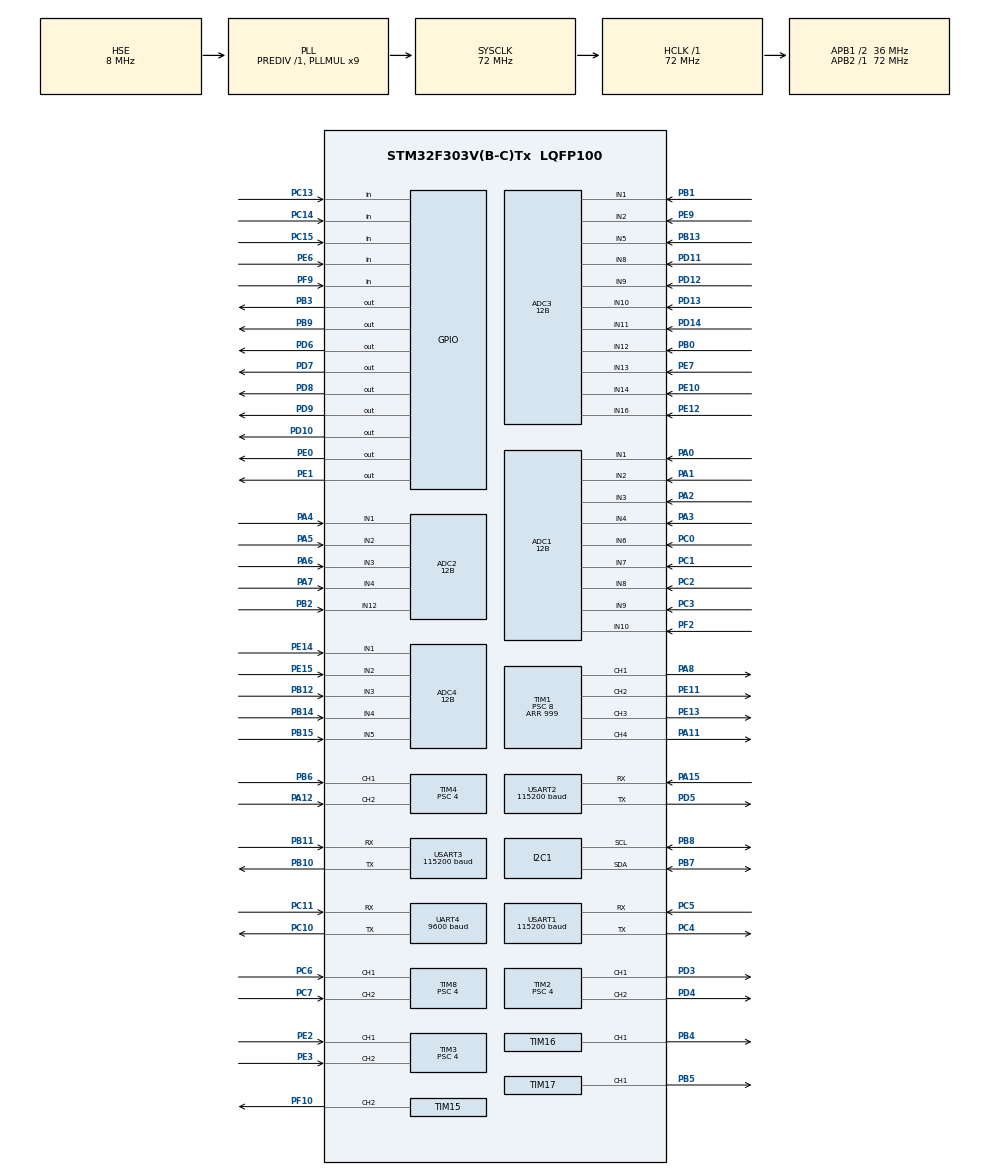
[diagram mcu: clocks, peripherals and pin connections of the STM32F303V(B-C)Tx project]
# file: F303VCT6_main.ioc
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ADC1.Channel-0\#ChannelRegularConversion=ADC_CHANNEL_1
ADC1.Channel-1\#ChannelRegularConversion=ADC_CHANNEL_2
ADC1.Channel-2\#ChannelRegularConversion=ADC_CHANNEL_3
ADC1.Channel-3\#ChannelRegularConversion=ADC_CHANNEL_4
ADC1.Channel-4\#ChannelRegularConversion=ADC_CHANNEL_6
ADC1.Channel-5\#ChannelRegularConversion=ADC_CHANNEL_7
ADC1.Channel-6\#ChannelRegularConversion=ADC_CHANNEL_8
ADC1.Channel-7\#ChannelRegularConversion=ADC_CHANNEL_9
ADC1.Channel-9\#ChannelRegularConversion=ADC_CHANNEL_10
ADC1.ClockPrescaler=ADC_CLOCK_SYNC_PCLK_DIV4
ADC1.ContinuousConvMode=ENABLE
ADC1.DMAContinuousRequests=ENABLE
ADC1.DataAlign=ADC_DATAALIGN_RIGHT
ADC1.DiscontinuousConvMode=DISABLE
ADC1.EOCSelection=ADC_EOC_SINGLE_CONV
ADC1.EnableAnalogWatchDog1=false
ADC1.EnableAnalogWatchDog2=false
ADC1.EnableAnalogWatchDog3=false
ADC1.EnableInjectedConversion=DISABLE
ADC1.EnableRegularConversion=ENABLE
ADC1.ExternalTrigConv=ADC_SOFTWARE_START
ADC1.ExternalTrigConvEdge=ADC_EXTERNALTRIGCONVEDGE_NONE
ADC1.LowPowerAutoWait=DISABLE
ADC1.NbrOfConversion=9
ADC1.NbrOfConversionFlag=1
ADC1.Offset-0\#ChannelRegularConversion=0
ADC1.Offset-1\#ChannelRegularConversion=0
ADC1.Offset-2\#ChannelRegularConversion=0
ADC1.Offset-3\#ChannelRegularConversion=0
ADC1.Offset-4\#ChannelRegularConversion=0
ADC1.Offset-5\#ChannelRegularConversion=0
ADC1.Offset-6\#ChannelRegularConversion=0
ADC1.Offset-7\#ChannelRegularConversion=0
ADC1.Offset-9\#ChannelRegularConversion=0
ADC1.OffsetNumber-0\#ChannelRegularConversion=ADC_OFFSET_NONE
ADC1.OffsetNumber-1\#ChannelRegularConversion=ADC_OFFSET_NONE
ADC1.OffsetNumber-2\#ChannelRegularConversion=ADC_OFFSET_NONE
ADC1.OffsetNumber-3\#ChannelRegularConversion=ADC_OFFSET_NONE
ADC1.OffsetNumber-4\#ChannelRegularConversion=ADC_OFFSET_NONE
ADC1.OffsetNumber-5\#ChannelRegularConversion=ADC_OFFSET_NONE
ADC1.OffsetNumber-6\#ChannelRegularConversion=ADC_OFFSET_NONE
ADC1.OffsetNumber-7\#ChannelRegularConversion=ADC_OFFSET_NONE
ADC1.OffsetNumber-9\#ChannelRegularConversion=ADC_OFFSET_NONE
ADC1.Overrun=ADC_OVR_DATA_OVERWRITTEN
ADC1.Rank-0\#ChannelRegularConversion=1
ADC1.Rank-1\#ChannelRegularConversion=2
ADC1.Rank-2\#ChannelRegularConversion=3
ADC1.Rank-3\#ChannelRegularConversion=4
ADC1.Rank-4\#ChannelRegularConversion=5
ADC1.Rank-5\#ChannelRegularConversion=6
ADC1.Rank-6\#ChannelRegularConversion=7
ADC1.Rank-7\#ChannelRegularConversion=8
ADC1.Rank-9\#ChannelRegularConversion=9
ADC1.Resolution=ADC_RESOLUTION_12B
ADC1.SamplingTime-0\#ChannelRegularConversion=ADC_SAMPLETIME_181CYCLES_5
ADC1.SamplingTime-1\#ChannelRegularConversion=ADC_SAMPLETIME_181CYCLES_5
ADC1.SamplingTime-2\#ChannelRegularConversion=ADC_SAMPLETIME_181CYCLES_5
ADC1.SamplingTime-3\#ChannelRegularConversion=ADC_SAMPLETIME_181CYCLES_5
ADC1.SamplingTime-4\#ChannelRegularConversion=ADC_SAMPLETIME_181CYCLES_5
ADC1.SamplingTime-5\#ChannelRegularConversion=ADC_SAMPLETIME_181CYCLES_5
ADC1.SamplingTime-6\#ChannelRegularConversion=ADC_SAMPLETIME_181CYCLES_5
ADC1.SamplingTime-7\#ChannelRegularConversion=ADC_SAMPLETIME_181CYCLES_5
ADC1.SamplingTime-9\#ChannelRegularConversion=ADC_SAMPLETIME_181CYCLES_5
ADC1.ScanConvMode=ADC_SCAN_ENABLE
ADC1.master=1
ADC2.Channel-0\#ChannelRegularConversion=ADC_CHANNEL_1
ADC2.Channel-1\#ChannelRegularConversion=ADC_CHANNEL_2
ADC2.Channel-2\#ChannelRegularConversion=ADC_CHANNEL_3
ADC2.Channel-3\#ChannelRegularConversion=ADC_CHANNEL_4
ADC2.Channel-4\#ChannelRegularConversion=ADC_CHANNEL_12
ADC2.ClockPrescaler=ADC_CLOCK_SYNC_PCLK_DIV4
ADC2.ContinuousConvMode=ENABLE
ADC2.DMAContinuousRequests=ENABLE
ADC2.DataAlign=ADC_DATAALIGN_RIGHT
ADC2.DiscontinuousConvMode=DISABLE
ADC2.EOCSelection=ADC_EOC_SINGLE_CONV
ADC2.EnableAnalogWatchDog1=false
ADC2.EnableAnalogWatchDog2=false
ADC2.EnableAnalogWatchDog3=false
ADC2.EnableInjectedConversion=DISABLE
ADC2.EnableRegularConversion=ENABLE
ADC2.ExternalTrigConv=ADC_SOFTWARE_START
ADC2.ExternalTrigConvEdge=ADC_EXTERNALTRIGCONVEDGE_NONE
ADC2.LowPowerAutoWait=DISABLE
ADC2.NbrOfConversion=5
ADC2.NbrOfConversionFlag=1
ADC2.Offset-0\#ChannelRegularConversion=0
ADC2.Offset-1\#ChannelRegularConversion=0
ADC2.Offset-2\#ChannelRegularConversion=0
ADC2.Offset-3\#ChannelRegularConversion=0
ADC2.Offset-4\#ChannelRegularConversion=0
ADC2.OffsetNumber-0\#ChannelRegularConversion=ADC_OFFSET_NONE
ADC2.OffsetNumber-1\#ChannelRegularConversion=ADC_OFFSET_NONE
ADC2.OffsetNumber-2\#ChannelRegularConversion=ADC_OFFSET_NONE
ADC2.OffsetNumber-3\#ChannelRegularConversion=ADC_OFFSET_NONE
ADC2.OffsetNumber-4\#ChannelRegularConversion=ADC_OFFSET_NONE
ADC2.Overrun=ADC_OVR_DATA_OVERWRITTEN
ADC2.Rank-0\#ChannelRegularConversion=1
ADC2.Rank-1\#ChannelRegularConversion=2
ADC2.Rank-2\#ChannelRegularConversion=3
ADC2.Rank-3\#ChannelRegularConversion=4
ADC2.Rank-4\#ChannelRegularConversion=5
ADC2.Resolution=ADC_RESOLUTION_12B
ADC2.SamplingTime-0\#ChannelRegularConversion=ADC_SAMPLETIME_181CYCLES_5
ADC2.SamplingTime-1\#ChannelRegularConversion=ADC_SAMPLETIME_181CYCLES_5
ADC2.SamplingTime-2\#ChannelRegularConversion=ADC_SAMPLETIME_181CYCLES_5
ADC2.SamplingTime-3\#ChannelRegularConversion=ADC_SAMPLETIME_181CYCLES_5
ADC2.SamplingTime-4\#ChannelRegularConversion=ADC_SAMPLETIME_181CYCLES_5
ADC2.ScanConvMode=ADC_SCAN_ENABLE
ADC3.Channel-0\#ChannelRegularConversion=ADC_CHANNEL_1
ADC3.Channel-1\#ChannelRegularConversion=ADC_CHANNEL_2
ADC3.Channel-10\#ChannelRegularConversion=ADC_CHANNEL_16
ADC3.Channel-2\#ChannelRegularConversion=ADC_CHANNEL_5
ADC3.Channel-3\#ChannelRegularConversion=ADC_CHANNEL_8
ADC3.Channel-4\#ChannelRegularConversion=ADC_CHANNEL_9
ADC3.Channel-5\#ChannelRegularConversion=ADC_CHANNEL_10
ADC3.Channel-6\#ChannelRegularConversion=ADC_CHANNEL_11
ADC3.Channel-7\#ChannelRegularConversion=ADC_CHANNEL_12
ADC3.Channel-8\#ChannelRegularConversion=ADC_CHANNEL_13
ADC3.Channel-9\#ChannelRegularConversion=ADC_CHANNEL_14
ADC3.ClockPrescaler=ADC_CLOCK_SYNC_PCLK_DIV4
ADC3.ContinuousConvMode=ENABLE
ADC3.DMAContinuousRequests=ENABLE
ADC3.DataAlign=ADC_DATAALIGN_RIGHT
ADC3.DiscontinuousConvMode=DISABLE
ADC3.EOCSelection=ADC_EOC_SINGLE_CONV
ADC3.EnableAnalogWatchDog1=false
ADC3.EnableAnalogWatchDog2=false
ADC3.EnableAnalogWatchDog3=false
ADC3.EnableInjectedConversion=DISABLE
ADC3.EnableRegularConversion=ENABLE
ADC3.ExternalTrigConv=ADC_SOFTWARE_START
ADC3.ExternalTrigConvEdge=ADC_EXTERNALTRIGCONVEDGE_NONE
ADC3.LowPowerAutoWait=DISABLE
ADC3.NbrOfConversion=11
ADC3.NbrOfConversionFlag=1
ADC3.Offset-0\#ChannelRegularConversion=0
ADC3.Offset-1\#ChannelRegularConversion=0
ADC3.Offset-10\#ChannelRegularConversion=0
ADC3.Offset-2\#ChannelRegularConversion=0
ADC3.Offset-3\#ChannelRegularConversion=0
ADC3.Offset-4\#ChannelRegularConversion=0
ADC3.Offset-5\#ChannelRegularConversion=0
ADC3.Offset-6\#ChannelRegularConversion=0
ADC3.Offset-7\#ChannelRegularConversion=0
ADC3.Offset-8\#ChannelRegularConversion=0
ADC3.Offset-9\#ChannelRegularConversion=0
ADC3.OffsetNumber-0\#ChannelRegularConversion=ADC_OFFSET_NONE
ADC3.OffsetNumber-1\#ChannelRegularConversion=ADC_OFFSET_NONE
ADC3.OffsetNumber-10\#ChannelRegularConversion=ADC_OFFSET_NONE
ADC3.OffsetNumber-2\#ChannelRegularConversion=ADC_OFFSET_NONE
ADC3.OffsetNumber-3\#ChannelRegularConversion=ADC_OFFSET_NONE
ADC3.OffsetNumber-4\#ChannelRegularConversion=ADC_OFFSET_NONE
ADC3.OffsetNumber-5\#ChannelRegularConversion=ADC_OFFSET_NONE
ADC3.OffsetNumber-6\#ChannelRegularConversion=ADC_OFFSET_NONE
ADC3.OffsetNumber-7\#ChannelRegularConversion=ADC_OFFSET_NONE
ADC3.OffsetNumber-8\#ChannelRegularConversion=ADC_OFFSET_NONE
ADC3.OffsetNumber-9\#ChannelRegularConversion=ADC_OFFSET_NONE
ADC3.Overrun=ADC_OVR_DATA_OVERWRITTEN
ADC3.Rank-0\#ChannelRegularConversion=1
ADC3.Rank-1\#ChannelRegularConversion=2
ADC3.Rank-10\#ChannelRegularConversion=11
ADC3.Rank-2\#ChannelRegularConversion=3
ADC3.Rank-3\#ChannelRegularConversion=4
ADC3.Rank-4\#ChannelRegularConversion=5
ADC3.Rank-5\#ChannelRegularConversion=6
ADC3.Rank-6\#ChannelRegularConversion=7
ADC3.Rank-7\#ChannelRegularConversion=8
ADC3.Rank-8\#ChannelRegularConversion=9
ADC3.Rank-9\#ChannelRegularConversion=10
ADC3.Resolution=ADC_RESOLUTION_12B
ADC3.SamplingTime-0\#ChannelRegularConversion=ADC_SAMPLETIME_181CYCLES_5
ADC3.SamplingTime-1\#ChannelRegularConversion=ADC_SAMPLETIME_181CYCLES_5
ADC3.SamplingTime-10\#ChannelRegularConversion=ADC_SAMPLETIME_181CYCLES_5
ADC3.SamplingTime-2\#ChannelRegularConversion=ADC_SAMPLETIME_181CYCLES_5
ADC3.SamplingTime-3\#ChannelRegularConversion=ADC_SAMPLETIME_181CYCLES_5
ADC3.SamplingTime-4\#ChannelRegularConversion=ADC_SAMPLETIME_181CYCLES_5
ADC3.SamplingTime-5\#ChannelRegularConversion=ADC_SAMPLETIME_181CYCLES_5
ADC3.SamplingTime-6\#ChannelRegularConversion=ADC_SAMPLETIME_181CYCLES_5
ADC3.SamplingTime-7\#ChannelRegularConversion=ADC_SAMPLETIME_181CYCLES_5
ADC3.SamplingTime-8\#ChannelRegularConversion=ADC_SAMPLETIME_181CYCLES_5
ADC3.SamplingTime-9\#ChannelRegularConversion=ADC_SAMPLETIME_181CYCLES_5
ADC3.ScanConvMode=ADC_SCAN_ENABLE
ADC3.master=1
ADC4.Channel-0\#ChannelRegularConversion=ADC_CHANNEL_1
ADC4.Channel-1\#ChannelRegularConversion=ADC_CHANNEL_2
ADC4.Channel-2\#ChannelRegularConversion=ADC_CHANNEL_3
ADC4.Channel-3\#ChannelRegularConversion=ADC_CHANNEL_4
ADC4.Channel-4\#ChannelRegularConversion=ADC_CHANNEL_5
ADC4.ClockPrescaler=ADC_CLOCK_SYNC_PCLK_DIV4
ADC4.ContinuousConvMode=ENABLE
ADC4.DMAContinuousRequests=ENABLE
ADC4.DataAlign=ADC_DATAALIGN_RIGHT
ADC4.DiscontinuousConvMode=DISABLE
ADC4.EOCSelection=ADC_EOC_SINGLE_CONV
ADC4.EnableAnalogWatchDog1=false
ADC4.EnableAnalogWatchDog2=false
ADC4.EnableAnalogWatchDog3=false
ADC4.EnableInjectedConversion=DISABLE
ADC4.EnableRegularConversion=ENABLE
ADC4.ExternalTrigConv=ADC_SOFTWARE_START
ADC4.ExternalTrigConvEdge=ADC_EXTERNALTRIGCONVEDGE_NONE
ADC4.LowPowerAutoWait=DISABLE
ADC4.NbrOfConversion=5
ADC4.NbrOfConversionFlag=1
ADC4.Offset-0\#ChannelRegularConversion=0
ADC4.Offset-1\#ChannelRegularConversion=0
ADC4.Offset-2\#ChannelRegularConversion=0
ADC4.Offset-3\#ChannelRegularConversion=0
ADC4.Offset-4\#ChannelRegularConversion=0
ADC4.OffsetNumber-0\#ChannelRegularConversion=ADC_OFFSET_NONE
ADC4.OffsetNumber-1\#ChannelRegularConversion=ADC_OFFSET_NONE
ADC4.OffsetNumber-2\#ChannelRegularConversion=ADC_OFFSET_NONE
ADC4.OffsetNumber-3\#ChannelRegularConversion=ADC_OFFSET_NONE
ADC4.OffsetNumber-4\#ChannelRegularConversion=ADC_OFFSET_NONE
ADC4.Overrun=ADC_OVR_DATA_OVERWRITTEN
ADC4.Rank-0\#ChannelRegularConversion=1
ADC4.Rank-1\#ChannelRegularConversion=2
ADC4.Rank-2\#ChannelRegularConversion=3
ADC4.Rank-3\#ChannelRegularConversion=4
ADC4.Rank-4\#ChannelRegularConversion=5
ADC4.Resolution=ADC_RESOLUTION_12B
ADC4.SamplingTime-0\#ChannelRegularConversion=ADC_SAMPLETIME_181CYCLES_5
ADC4.SamplingTime-1\#ChannelRegularConversion=ADC_SAMPLETIME_181CYCLES_5
ADC4.SamplingTime-2\#ChannelRegularConversion=ADC_SAMPLETIME_181CYCLES_5
ADC4.SamplingTime-3\#ChannelRegularConversion=ADC_SAMPLETIME_181CYCLES_5
ADC4.SamplingTime-4\#ChannelRegularConversion=ADC_SAMPLETIME_181CYCLES_5
ADC4.ScanConvMode=ADC_SCAN_ENABLE
Dma.ADC1.3.Direction=DMA_PERIPH_TO_MEMORY
Dma.ADC1.3.Instance=DMA1_Channel1
Dma.ADC1.3.MemDataAlignment=DMA_MDATAALIGN_HALFWORD
Dma.ADC1.3.MemInc=DMA_MINC_ENABLE
Dma.ADC1.3.Mode=DMA_CIRCULAR
Dma.ADC1.3.PeriphDataAlignment=DMA_PDATAALIGN_HALFWORD
Dma.ADC1.3.PeriphInc=DMA_PINC_DISABLE
Dma.ADC1.3.Priority=DMA_PRIORITY_LOW
Dma.ADC2.4.Direction=DMA_PERIPH_TO_MEMORY
Dma.ADC2.4.Instance=DMA2_Channel3
Dma.ADC2.4.MemDataAlignment=DMA_MDATAALIGN_HALFWORD
Dma.ADC2.4.MemInc=DMA_MINC_ENABLE
Dma.ADC2.4.Mode=DMA_CIRCULAR
Dma.ADC2.4.PeriphDataAlignment=DMA_PDATAALIGN_HALFWORD
Dma.ADC2.4.PeriphInc=DMA_PINC_DISABLE
Dma.ADC2.4.Priority=DMA_PRIORITY_LOW
Dma.ADC3.0.Direction=DMA_PERIPH_TO_MEMORY
Dma.ADC3.0.Instance=DMA2_Channel5
Dma.ADC3.0.MemDataAlignment=DMA_MDATAALIGN_HALFWORD
Dma.ADC3.0.MemInc=DMA_MINC_ENABLE
Dma.ADC3.0.Mode=DMA_CIRCULAR
Dma.ADC3.0.PeriphDataAlignment=DMA_PDATAALIGN_HALFWORD
Dma.ADC3.0.PeriphInc=DMA_PINC_DISABLE
Dma.ADC3.0.Priority=DMA_PRIORITY_LOW
Dma.ADC4.1.Direction=DMA_PERIPH_TO_MEMORY
Dma.ADC4.1.Instance=DMA2_Channel4
Dma.ADC4.1.MemDataAlignment=DMA_MDATAALIGN_HALFWORD
Dma.ADC4.1.MemInc=DMA_MINC_ENABLE
Dma.ADC4.1.Mode=DMA_CIRCULAR
Dma.ADC4.1.PeriphDataAlignment=DMA_PDATAALIGN_HALFWORD
Dma.ADC4.1.PeriphInc=DMA_PINC_DISABLE
Dma.ADC4.1.Priority=DMA_PRIORITY_LOW
Dma.Request0=ADC3
Dma.Request1=ADC4
Dma.Request2=USART2_RX
Dma.Request3=ADC1
Dma.Request4=ADC2
Dma.USART2_RX.2.Direction=DMA_PERIPH_TO_MEMORY
Dma.USART2_RX.2.Instance=DMA1_Channel6
Dma.USART2_RX.2.MemDataAlignment=DMA_MDATAALIGN_BYTE
Dma.USART2_RX.2.MemInc=DMA_MINC_ENABLE
Dma.USART2_RX.2.Mode=DMA_CIRCULAR
Dma.USART2_RX.2.PeriphDataAlignment=DMA_PDATAALIGN_BYTE
Dma.USART2_RX.2.PeriphInc=DMA_PINC_DISABLE
Dma.USART2_RX.2.Priority=DMA_PRIORITY_LOW
I2C1.I2C_Rise_Time=300
I2C1.Timing=0x00401D2A
Mcu.Family=STM32F3
Mcu.Name=STM32F303V(B-C)Tx
Mcu.Package=LQFP100
NVIC.DMA1_Channel1_IRQn=true\:0\:0\:false\:false\:true\:false
NVIC.DMA1_Channel6_IRQn=true\:2\:0\:true\:false\:true\:false
NVIC.DMA2_Channel3_IRQn=true\:0\:0\:false\:false\:true\:false
NVIC.DMA2_Channel4_IRQn=true\:4\:0\:true\:false\:true\:false
NVIC.DMA2_Channel5_IRQn=true\:6\:0\:true\:false\:true\:false
NVIC.PriorityGroup=NVIC_PRIORITYGROUP_4
NVIC.TIM6_DAC_IRQn=true\:5\:0\:true\:false\:true\:true
PA0.Mode=IN1-Single-Ended
PA0.Signal=ADC1_IN1
PA1.Mode=IN2-Single-Ended
PA1.Signal=ADC1_IN2
PA11.Signal=S_TIM1_CH4
PA12.Signal=S_TIM4_CH2
PA13.Mode=Serial_Wire
PA13.Signal=SYS_JTMS-SWDIO
PA14.Mode=Serial_Wire
PA14.Signal=SYS_JTCK-SWCLK
PA15.Mode=Asynchronous
PA15.Signal=USART2_RX
PA2.Mode=IN3-Single-Ended
PA2.Signal=ADC1_IN3
PA3.Mode=IN4-Single-Ended
PA3.Signal=ADC1_IN4
PA4.Mode=IN1-Single-Ended
PA4.Signal=ADC2_IN1
PA5.Mode=IN2-Single-Ended
PA5.Signal=ADC2_IN2
PA6.Mode=IN3-Single-Ended
PA6.Signal=ADC2_IN3
PA7.Mode=IN4-Single-Ended
PA7.Signal=ADC2_IN4
PA8.Signal=S_TIM1_CH1
PB0.Mode=IN12-Single-Ended
PB0.Signal=ADC3_IN12
PB1.Mode=IN1-Single-Ended
PB1.Signal=ADC3_IN1
PB10.Mode=Asynchronous
PB10.Signal=USART3_TX
PB11.Mode=Asynchronous
PB11.Signal=USART3_RX
PB12.Mode=IN3-Single-Ended
PB12.Signal=ADC4_IN3
PB13.Mode=IN5-Single-Ended
PB13.Signal=ADC3_IN5
PB14.Mode=IN4-Single-Ended
PB14.Signal=ADC4_IN4
PB15.Mode=IN5-Single-Ended
PB15.Signal=ADC4_IN5
PB2.Mode=IN12-Single-Ended
PB2.Signal=ADC2_IN12
PB3.Signal=GPIO_Output
PB4.Signal=S_TIM16_CH1
PB5.Signal=S_TIM17_CH1
PB6.Signal=S_TIM4_CH1
PB7.Mode=I2C
PB7.Signal=I2C1_SDA
PB8.Mode=I2C
PB8.Signal=I2C1_SCL
PB9.Signal=GPIO_Output
PC0.Signal=ADCx_IN6
PC1.Signal=ADCx_IN7
PC10.Mode=Asynchronous
PC10.Signal=UART4_TX
PC11.Mode=Asynchronous
PC11.Signal=UART4_RX
PC13.Signal=GPIO_Input
PC14-OSC32_IN.Signal=GPIO_Input
PC15-OSC32_OUT.Signal=GPIO_Input
PC2.Signal=ADCx_IN8
PC3.Signal=ADCx_IN9
PC4.Mode=Asynchronous
PC4.Signal=USART1_TX
PC5.Mode=Asynchronous
PC5.Signal=USART1_RX
PC6.Signal=S_TIM8_CH1
PC7.Signal=S_TIM8_CH2
PD10.Signal=GPIO_Output
PD11.Signal=ADCx_IN8P
PD12.Signal=ADCx_IN9P
PD13.Signal=ADCx_IN10P
PD14.Signal=ADCx_IN11
PD3.Signal=S_TIM2_CH1_ETR
PD4.Signal=S_TIM2_CH2
PD5.Mode=Asynchronous
PD5.Signal=USART2_TX
PD6.Signal=GPIO_Output
PD7.Signal=GPIO_Output
PD8.Signal=GPIO_Output
PD9.Signal=GPIO_Output
PE0.Signal=GPIO_Output
PE1.Signal=GPIO_Output
PE10.Mode=IN14-Single-Ended
PE10.Signal=ADC3_IN14
PE11.Signal=S_TIM1_CH2
PE12.Mode=IN16-Single-Ended
PE12.Signal=ADC3_IN16
PE13.Signal=S_TIM1_CH3
PE14.Mode=IN1-Single-Ended
PE14.Signal=ADC4_IN1
PE15.Mode=IN2-Single-Ended
PE15.Signal=ADC4_IN2
PE2.Signal=S_TIM3_CH1
PE3.Signal=S_TIM3_CH2
PE6.Signal=GPIO_Input
PE7.Mode=IN13-Single-Ended
PE7.Signal=ADC3_IN13
PE9.Mode=IN2-Single-Ended
PE9.Signal=ADC3_IN2
PF0-OSC_IN.Mode=HSE-External-Oscillator
PF0-OSC_IN.Signal=RCC_OSC_IN
PF1-OSC_OUT.Mode=HSE-External-Oscillator
PF1-OSC_OUT.Signal=RCC_OSC_OUT
PF10.Signal=S_TIM15_CH2
PF2.Signal=ADCx_IN10
PF9.Signal=GPIO_Input
ProjectManager.HeapSize=0x200
ProjectManager.StackSize=0x400
ProjectManager.TargetToolchain=TrueSTUDIO
RCC.AHBFreq_Value=72000000
RCC.APB1CLKDivider=RCC_HCLK_DIV2
RCC.APB1Freq_Value=36000000
RCC.APB1TimFreq_Value=72000000
RCC.APB2Freq_Value=72000000
RCC.APB2TimFreq_Value=72000000
RCC.CortexFreq_Value=72000000
RCC.HCLKFreq_Value=72000000
RCC.HSE_VALUE=8000000
RCC.HSI_VALUE=8000000
RCC.LSE_VALUE=32768
RCC.PLLMUL=RCC_PLL_MUL9
RCC.PLLSourceVirtual=RCC_PLLSOURCE_HSE
RCC.SYSCLKFreq_VALUE=72000000
RCC.SYSCLKSourceVirtual=RCC_SYSCLKSOURCE_PLLCLK
RCC.USBFreq_Value=72000000
SH.ADCx_IN10.0=ADC1_IN10,IN10-Single-Ended
SH.ADCx_IN10P.0=ADC3_IN10,IN10-Single-Ended
SH.ADCx_IN11.0=ADC3_IN11,IN11-Single-Ended
SH.ADCx_IN6.0=ADC1_IN6,IN6-Single-Ended
SH.ADCx_IN7.0=ADC1_IN7,IN7-Single-Ended
SH.ADCx_IN8.0=ADC1_IN8,IN8-Single-Ended
SH.ADCx_IN8P.0=ADC3_IN8,IN8-Single-Ended
SH.ADCx_IN9.0=ADC1_IN9,IN9-Single-Ended
SH.ADCx_IN9P.0=ADC3_IN9,IN9-Single-Ended
SH.S_TIM15_CH2.0=TIM15_CH2,PWM Generation2 CH2
SH.S_TIM16_CH1.0=TIM16_CH1,PWM Generation1 CH1
SH.S_TIM17_CH1.0=TIM17_CH1,PWM Generation1 CH1
SH.S_TIM1_CH1.0=TIM1_CH1,PWM Generation1 CH1
SH.S_TIM1_CH2.0=TIM1_CH2,PWM Generation2 CH2
SH.S_TIM1_CH3.0=TIM1_CH3,PWM Generation3 CH3
SH.S_TIM1_CH4.0=TIM1_CH4,PWM Generation4 CH4
SH.S_TIM2_CH1_ETR.0=TIM2_CH1,PWM Generation1 CH1
SH.S_TIM2_CH2.0=TIM2_CH2,PWM Generation2 CH2
SH.S_TIM3_CH1.0=TIM3_CH1,Encoder_Interface
SH.S_TIM3_CH2.0=TIM3_CH2,Encoder_Interface
SH.S_TIM4_CH1.0=TIM4_CH1,Encoder_Interface
SH.S_TIM4_CH2.0=TIM4_CH2,Encoder_Interface
SH.S_TIM8_CH1.0=TIM8_CH1,Encoder_Interface
SH.S_TIM8_CH2.0=TIM8_CH2,Encoder_Interface
TIM1.Channel-PWM\ Generation1\ CH1=TIM_CHANNEL_1
TIM1.Channel-PWM\ Generation2\ CH2=TIM_CHANNEL_2
TIM1.Channel-PWM\ Generation3\ CH3=TIM_CHANNEL_3
TIM1.Channel-PWM\ Generation4\ CH4=TIM_CHANNEL_4
TIM1.Period=999
TIM1.Prescaler=8
TIM15.Channel-PWM\ Generation2\ CH2=TIM_CHANNEL_2
TIM15.Period=9999
TIM15.Prescaler=144
TIM16.Channel=TIM_CHANNEL_1
TIM16.Period=9999
TIM16.Prescaler=144
TIM17.Channel=TIM_CHANNEL_1
TIM17.Period=9999
TIM17.Prescaler=144
TIM2.Channel-PWM\ Generation1\ CH1=TIM_CHANNEL_1
TIM2.Channel-PWM\ Generation2\ CH2=TIM_CHANNEL_2
TIM2.Period=999
TIM2.Prescaler=4
TIM3.Period=60000
TIM3.Prescaler=4
TIM4.Period=60000
TIM4.Prescaler=4
TIM6.Period=999
TIM6.Prescaler=36
TIM8.Period=60000
TIM8.Prescaler=4
UART4.BaudRate=9600
USART1.BaudRate=115200
USART1.SwapParam=ADVFEATURE_SWAP_ENABLE
USART1.VirtualMode-Asynchronous=VM_ASYNC
USART2.BaudRate=115200
USART2.VirtualMode-Asynchronous=VM_ASYNC
USART3.BaudRate=115200
USART3.Parity=PARITY_EVEN
USART3.VirtualMode-Asynchronous=VM_ASYNC
USART3.WordLength=WORDLENGTH_9B
VP_TIM16_VS_ClockSourceINT.Mode=Enable_Timer
VP_TIM17_VS_ClockSourceINT.Mode=Enable_Timer
VP_TIM6_VS_ClockSourceINT.Mode=Enable_Timer
board=custom

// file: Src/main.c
/**
  ******************************************************************************
  * @file           : main.c
  * @brief          : Main program body
  ******************************************************************************
  ** This notice applies to any and all portions of this file
  * that are not between comment pairs USER CODE BEGIN and
  * USER CODE END. Other portions of this file, whether
  * inserted by the user or by software development tools
  * are owned by their respective copyright owners.
  *
  * COPYRIGHT(c) 2019 STMicroelectronics
  *
  * Redistribution and use in source and binary forms, with or without modification,
  * are permitted provided that the following conditions are met:
  *   1. Redistributions of source code must retain the above copyright notice,
  *      this list of conditions and the following disclaimer.
  *   2. Redistributions in binary form must reproduce the above copyright notice,
  *      this list of conditions and the following disclaimer in the documentation
  *      and/or other materials provided with the distribution.
  *   3. Neither the name of STMicroelectronics nor the names of its contributors
  *      may be used to endorse or promote products derived from this software
  *      without specific prior written permission.
  *
  * THIS SOFTWARE IS PROVIDED BY THE COPYRIGHT HOLDERS AND CONTRIBUTORS "AS IS"
  * AND ANY EXPRESS OR IMPLIED WARRANTIES, INCLUDING, BUT NOT LIMITED TO, THE
  * IMPLIED WARRANTIES OF MERCHANTABILITY AND FITNESS FOR A PARTICULAR PURPOSE ARE
  * DISCLAIMED. IN NO EVENT SHALL THE COPYRIGHT HOLDER OR CONTRIBUTORS BE LIABLE
  * FOR ANY DIRECT, INDIRECT, INCIDENTAL, SPECIAL, EXEMPLARY, OR CONSEQUENTIAL
  * DAMAGES (INCLUDING, BUT NOT LIMITED TO, PROCUREMENT OF SUBSTITUTE GOODS OR
  * SERVICES; LOSS OF USE, DATA, OR PROFITS; OR BUSINESS INTERRUPTION) HOWEVER
  * CAUSED AND ON ANY THEORY OF LIABILITY, WHETHER IN CONTRACT, STRICT LIABILITY,
  * OR TORT (INCLUDING NEGLIGENCE OR OTHERWISE) ARISING IN ANY WAY OUT OF THE USE
  * OF THIS SOFTWARE, EVEN IF ADVISED OF THE POSSIBILITY OF SUCH DAMAGE.
  *
  ******************************************************************************
  */
#include "main.h"
#include "stm32f3xx_hal.h"
#include "adc.h"
#include "dma.h"
#include "i2c.h"
#include "tim.h"
#include "usart.h"
#include "gpio.h"

/* USER CODE BEGIN Includes */
#include "management.h"
#include <stdio.h>
/* USER CODE END Includes */

/* USER CODE BEGIN PV */
/* Private variables ---------------------------------------------------------*/

/* USER CODE END PV */

void SystemClock_Config(void);

/* USER CODE BEGIN PFP */
/* Private function prototypes -----------------------------------------------*/
void HAL_UART_RxCpltCallback(UART_HandleTypeDef *huart);
void Calibration();
void state_print();
void test();
void main_run();
void test2();
/* USER CODE END PFP */

/* USER CODE BEGIN 0 */
uint8_t mode;
uint8_t shyuukai=0;

 /* USER CODE END 0 */

int main(void)
{

  /* MCU Configuration----------------------------------------------------------*/

  /* Reset of all peripherals, Initializes the Flash interface and the Systick. */
  HAL_Init();

  /* Configure the system clock */
  SystemClock_Config();

  /* Initialize all configured peripherals */
  MX_GPIO_Init();
  MX_DMA_Init();
  MX_ADC1_Init();
  MX_ADC2_Init();
  MX_ADC3_Init();
  MX_USART1_UART_Init();
  MX_ADC4_Init();
  MX_USART2_UART_Init();
  MX_USART3_UART_Init();
  MX_TIM1_Init();
  MX_TIM2_Init();
  MX_TIM6_Init();
  MX_I2C1_Init();
  MX_UART4_Init();
  MX_TIM8_Init();
  MX_TIM4_Init();
  MX_TIM3_Init();
  MX_TIM17_Init();
  MX_TIM15_Init();
  MX_TIM16_Init();
  /* USER CODE BEGIN 2 */
  xprintf_init(&huart1);
  JY901_init(&hi2c1);
  oled_i2c_to_oled(&hi2c1);
  DFPlayer_init(&huart4);
  oled_returnhome();
  oled_puts("Is The Order a");
  oled_setcursor(1,2);
  oled_puts("Lancer Robot?");
  HAL_Delay(500);
  DFPlayer_setvolume(0x12);
  HAL_Delay(500);
  DFPlayer_playmp3(1);
  HOUI_def=JY901_def_set();

  if(HAL_TIM_Encoder_Init(&htim3, &sConfig) != HAL_OK){Error_Handler();}
  HAL_TIM_Encoder_Start(&htim3, TIM_CHANNEL_ALL);
  TIM3->CNT=30000;

  if(HAL_TIM_Encoder_Init(&htim4, &sConfig) != HAL_OK){Error_Handler();}
  HAL_TIM_Encoder_Start(&htim4, TIM_CHANNEL_ALL);
  TIM4->CNT=30000;

  if(HAL_TIM_Encoder_Init(&htim8, &sConfig) != HAL_OK){Error_Handler();}
  HAL_TIM_Encoder_Start(&htim8, TIM_CHANNEL_ALL);
  TIM8->CNT=30000;

  if (HAL_ADC_Start_DMA(&hadc1, (uint32_t *)ADCdata1,9) != HAL_OK){Error_Handler();}

  if (HAL_ADC_Start_DMA(&hadc2, (uint32_t *)ADCdata2,sizeof(ADCdata2)) != HAL_OK){Error_Handler();}

  if (HAL_ADC_Start_DMA(&hadc3, (uint32_t *)ADCdata3,sizeof(ADCdata3)) != HAL_OK){Error_Handler();}

  if (HAL_ADC_Start_DMA(&hadc4, (uint32_t *)ADCdata4,sizeof(ADCdata4)) != HAL_OK){Error_Handler();}

  if (HAL_UART_Receive_DMA(&huart2, (uint8_t *)Rxbuf,sizeof(Rxbuf)) != HAL_OK){Error_Handler();}

  HOUI_def=JY901_def_set();

  Rxbuf[0]=0;
  Rxbuf[1]=90;
  Rxbuf[2]=0;
  data[0]=90;
  data[1]=0;
  /* USER CODE END 2 */

  /* Infinite loop */
  while (1)
  {

  /* USER CODE BEGIN 3 */
	  mofu:
	  	  	 mode=//HAL_GPIO_ReadPin(GPIOE,GPIO_PIN_6)*4+
	  	  			 HAL_GPIO_ReadPin(GPIOC,GPIO_PIN_13)*2 +HAL_GPIO_ReadPin(GPIOC,GPIO_PIN_14);
	  	  	  switch(mode){
	  	  	  case 0:
	  	  		  if(HAL_GPIO_ReadPin(GPIOC,GPIO_PIN_15)==1){
	  	  			  HOUI_def=JY901_def_set();
	  	  			  while(HAL_GPIO_ReadPin(GPIOF,GPIO_PIN_9)){
	  	  				  	  servo(90,100,95,90);
							ics_set_pos1(0,map_a(90-3,0,180,4833,10166));
							ics_set_pos1(1,map_a(90,0,180,4833,10166));
							motor_move(0,0,0);
							xprintf("digree=%d\r\n",line_get_data_poorly_made());
							oled_returnhome();
							oled_puts("main_run waiting ");
							oled_setcursor(1,0);
							oled_puts("     for start   ");
							if(HAL_GPIO_ReadPin(GPIOC,GPIO_PIN_15)==0){goto mofu;}
							HAL_GPIO_TogglePin(GPIOD,GPIO_PIN_10);
	  	  			  	}
	  	  			  	  DFPlayer_setvolume(0x20);
	  	  			  	oled_clear();
	  	  			    oled_returnhome();
	  	  			    oled_puts("main_run select ");
	  	  			    oled_setcursor(1,0);
	  	  			    oled_puts("running");
	  	  			    HOUI_def=JY901_def_set();
					    TIM3->CNT=3000;
					    TIM4->CNT=3000;
					    TIM8->CNT=3000;
					    marker_count_data=0;
					    marker_count_data_=0;
					    while(HAL_GPIO_ReadPin(GPIOF,GPIO_PIN_9)==0){
	  	  			  		main_run();
	  	  			  	}
					    servo(90,100,95,90);
		  	  			ics_set_pos1(0,map_a(90-3,0,180,4833,10166));
		  	  			ics_set_pos1(1,map_a(90,0,180,4833,10166));
	  	  				motor_move(0,0,0);
	  	  		  }
	  	  		  else{
	  	  			  servo(90,100,95,90);
	  	  			  ics_set_pos1(0,map_a(90-3,0,180,4833,10166));
	  	  			  ics_set_pos1(1,map_a(90,0,180,4833,10166));
	  	 	  	  	  motor_move(0,0,0);
	  	  			  oled_returnhome();
	  	  			  oled_puts("main_run select");
	  	  			  oled_setcursor(1,0);
	  	  			  oled_puts("OK?     waiting ");
	  	  			  HAL_Delay(5);
	  	  		  HAL_GPIO_TogglePin(GPIOD,GPIO_PIN_10);
	  	  		  }
	  	  	  break;

	  	  	  case 1:
	  	  		  if(HAL_GPIO_ReadPin(GPIOC,GPIO_PIN_15)==1){
  	  			  test();
  	  			  servo(90,100,95,90);
  	  			  //ics_set_pos1(0,map_a(90,0,180,4833,10166));
  	  			  //ics_set_pos1(1,map_a(90,0,180,4833,10166));
  	 	  	  	  motor_move(0,0,0);
  	  			  oled_returnhome();
  	  			  oled_puts("testmode1 select");
  	  			  oled_setcursor(1,0);
  	  			  oled_puts("running         ");
  	  		  }
  	  		  else{
  	  			servo(90,100,95,90);
  	  			  ics_set_pos1(0,map_a(90-3,0,180,4833,10166));
  	  			  ics_set_pos1(1,map_a(90,0,180,4833,10166));
  	 	  	  	  motor_move(0,0,0);
  	  			  oled_returnhome();
  	  			  oled_puts("testmode1 select");
  	  			  oled_setcursor(1,0);
  	  			  oled_puts("OK?     waiting ");
  	  			  HAL_Delay(5);
  	  			xprintf(" Rx[0]=%d", Rxbuf[0]);
  	  				  xprintf(" Rx[1]=%d", Rxbuf[1]);
  	  				  xprintf(" Rx[2]=%d", Rxbuf[2]);
  	  				  xprintf(" data[0]=%d", data[0]);
  	  				  xprintf(" data[1]=%d", data[1]);
  	  				  	  xprintf("\r\n");
  	  		  HAL_GPIO_TogglePin(GPIOD,GPIO_PIN_10);
  	  		  }

	  	  	  break;

	  	  	  case 2:
	  	  		  if(HAL_GPIO_ReadPin(GPIOC,GPIO_PIN_15)==1){
  	  			  test2();
  	  			servo(90,100,95,90);
  	  			  //ics_set_pos1(0,map_a(90,0,180,4833,10166));
  	  			  //ics_set_pos1(1,map_a(90,0,180,4833,10166));
  	 	  	  	  motor_move(0,0,0);
  	  			  oled_returnhome();
  	  			  oled_puts("testmode2 select");
  	  			  oled_setcursor(1,0);
  	  			  oled_puts("running         ");
  	  		  }
  	  		  else{
  	  			servo(90,100,95,90);
  	  			  ics_set_pos1(0,map_a(90-3,0,180,4833,10166));
  	  			  ics_set_pos1(1,map_a(90,0,180,4833,10166));
  	 	  	  	  motor_move(0,0,0);
  	  			  oled_returnhome();
  	  			  oled_puts("testmode2 select");
  	  			  oled_setcursor(1,0);
  	  			  oled_puts("OK?     waiting ");
  	  			  HAL_Delay(5);
  	  		  HAL_GPIO_TogglePin(GPIOD,GPIO_PIN_10);
  	  		  }

	  	  	  break;

	  	  	  case 3:
	  	  		  if(HAL_GPIO_ReadPin(GPIOC,GPIO_PIN_15)==1){
  	  			  state_print();
  	  			servo(90,100,95,90);
  	  			  ics_set_pos1(0,map_a(90-3,0,180,4833,10166));
  	  			  ics_set_pos1(1,map_a(90,0,180,4833,10166));
  	 	  	  	  motor_move(0,0,0);
  	  			  oled_returnhome();
  	  			  oled_puts("State     select");
  	  			  oled_setcursor(1,0);
  	  			  oled_puts("running         ");
  	  		  }
  	  		  else{
  	  			servo(90,100,95,90);
  	  			  ics_set_pos1(0,map_a(90-3,0,180,4833,10166));
  	  			  ics_set_pos1(1,map_a(90,0,180,4833,10166));
  	 	  	  	  motor_move(0,0,0);
  	  			  oled_returnhome();
  	  			  oled_puts("State     select");
  	  			  oled_setcursor(1,0);
  	  			  oled_puts("OK?     waiting ");
  	  			  HAL_Delay(5);
  	  		  HAL_GPIO_TogglePin(GPIOD,GPIO_PIN_10);
  	  		  }

	  	  	  break;

	  	  	  default:
	  	  	  HAL_GPIO_TogglePin(GPIOD,GPIO_PIN_10);
	  	  	servo(90,100,95,90);
	  	  	  	  motor_move(0,0,0);
	  	  	  	  oled_returnhome();
	  	  	  	  oled_puts("select mode     ");
	  	  	  	  oled_setcursor(1,0);
	  	  	  	  oled_puts("           SURF ");
	  	  	  	  HAL_Delay(5);
	  	  	  break;
	  	  	  }
  }
  /* USER CODE END 3 */

}

void SystemClock_Config(void)
{

  RCC_OscInitTypeDef RCC_OscInitStruct;
  RCC_ClkInitTypeDef RCC_ClkInitStruct;
  RCC_PeriphCLKInitTypeDef PeriphClkInit;

    /**Initializes the CPU, AHB and APB busses clocks
    */
  RCC_OscInitStruct.OscillatorType = RCC_OSCILLATORTYPE_HSI|RCC_OSCILLATORTYPE_HSE;
  RCC_OscInitStruct.HSEState = RCC_HSE_ON;
  RCC_OscInitStruct.HSEPredivValue = RCC_HSE_PREDIV_DIV1;
  RCC_OscInitStruct.HSIState = RCC_HSI_ON;
  RCC_OscInitStruct.HSICalibrationValue = 16;
  RCC_OscInitStruct.PLL.PLLState = RCC_PLL_ON;
  RCC_OscInitStruct.PLL.PLLSource = RCC_PLLSOURCE_HSE;
  RCC_OscInitStruct.PLL.PLLMUL = RCC_PLL_MUL9;
  if (HAL_RCC_OscConfig(&RCC_OscInitStruct) != HAL_OK)
  {
    _Error_Handler(__FILE__, __LINE__);
  }

    /**Initializes the CPU, AHB and APB busses clocks
    */
  RCC_ClkInitStruct.ClockType = RCC_CLOCKTYPE_HCLK|RCC_CLOCKTYPE_SYSCLK
                              |RCC_CLOCKTYPE_PCLK1|RCC_CLOCKTYPE_PCLK2;
  RCC_ClkInitStruct.SYSCLKSource = RCC_SYSCLKSOURCE_PLLCLK;
  RCC_ClkInitStruct.AHBCLKDivider = RCC_SYSCLK_DIV1;
  RCC_ClkInitStruct.APB1CLKDivider = RCC_HCLK_DIV2;
  RCC_ClkInitStruct.APB2CLKDivider = RCC_HCLK_DIV1;

  if (HAL_RCC_ClockConfig(&RCC_ClkInitStruct, FLASH_LATENCY_2) != HAL_OK)
  {
    _Error_Handler(__FILE__, __LINE__);
  }

  PeriphClkInit.PeriphClockSelection = RCC_PERIPHCLK_USART1|RCC_PERIPHCLK_USART2
                              |RCC_PERIPHCLK_USART3|RCC_PERIPHCLK_UART4
                              |RCC_PERIPHCLK_I2C1|RCC_PERIPHCLK_TIM1
                              |RCC_PERIPHCLK_TIM8;
  PeriphClkInit.Usart1ClockSelection = RCC_USART1CLKSOURCE_PCLK2;
  PeriphClkInit.Usart2ClockSelection = RCC_USART2CLKSOURCE_PCLK1;
  PeriphClkInit.Usart3ClockSelection = RCC_USART3CLKSOURCE_PCLK1;
  PeriphClkInit.Uart4ClockSelection = RCC_UART4CLKSOURCE_PCLK1;
  PeriphClkInit.I2c1ClockSelection = RCC_I2C1CLKSOURCE_HSI;
  PeriphClkInit.Tim1ClockSelection = RCC_TIM1CLK_HCLK;
  PeriphClkInit.Tim8ClockSelection = RCC_TIM8CLK_HCLK;
  if (HAL_RCCEx_PeriphCLKConfig(&PeriphClkInit) != HAL_OK)
  {
    _Error_Handler(__FILE__, __LINE__);
  }

    /**Configure the Systick interrupt time
    */
  HAL_SYSTICK_Config(HAL_RCC_GetHCLKFreq()/1000);

    /**Configure the Systick
    */
  HAL_SYSTICK_CLKSourceConfig(SYSTICK_CLKSOURCE_HCLK);

  /* SysTick_IRQn interrupt configuration */
  HAL_NVIC_SetPriority(SysTick_IRQn, 0, 0);
}

/* USER CODE BEGIN 4 */

void main_run(){
		float calc=0;
		uint16_t digree_now;
		int HOUI_NOW=0;
		int snens_data;
		int mofu=1;
		digree_now=line_get_data_poorly_made();
		if(line_get_marker()==10){
			marker_count_data++;
		}
		if(marker_count_data>=10){
			shyuukai=1;
			marker_count_data=0;
		}
		if(marker_count_data_ != marker_count_data){
			marker_count_data_=marker_count_data;
 			 TIM3->CNT=30000;
		}

	  if(digree_now<360){
		  if(marker_count_data==1 ){//垂直標的
			  if((TIM3->CNT)>29700 && (TIM3->CNT)<29830){
				  HOUI_NOW=JY901_yaw_get(HOUI_def);
				  if(HOUI_NOW>180){
					  HOUI_NOW=HOUI_NOW-360;
				  }
	  			   ics_set_pos1(0,map_a((120-3)-HOUI_NOW,0,180,4833,10166));
	  			  DFPlayer_playmp3(3);
			  }
			  else{
				  ics_set_pos1(0,map_a(90-3,0,180,4833,10166));
			  }
		  }
		  if(marker_count_data==2){//垂直標的
			  if((TIM3->CNT)>29600 && (TIM3->CNT)<29770){
				  HOUI_NOW=JY901_yaw_get(HOUI_def);
				  if(HOUI_NOW>180){
					  HOUI_NOW=HOUI_NOW-360;
				  }
	  			   ics_set_pos1(0,map_a((128-3)-HOUI_NOW,0,180,4833,10166));
			  }
			  else{
				  ics_set_pos1(0,map_a(90-3,0,180,4833,10166));
			  }
		  }
		  if(marker_count_data==3){//横移動
			  servo(90,100,90,90);
			  while((TIM3->CNT)>29900){//少し前出る
				  digree_now=line_get_data_poorly_made();
				  if(digree_now<180){
					 calc=digree_now*(sqrt(digree_now*2.3))/16;
					 HOUI_Correction(0);
					 motor_move(125,(uint16_t)calc,800);
				 }
				 else{
					 calc=(360-digree_now)*(sqrt((360-digree_now)*2.3))/16;
					 HOUI_Correction(0);
					 motor_move(125,(uint16_t)(360.0-calc),800);
				 }
			  }
			  	  	 motor_move(0,0,0);
					 TIM4->CNT=30000;
					 while(TIM4->CNT>29530){//真ん中まで移動
						 HOUI_Correction(0);
						 motor_move(125,270,500);
						 }

					 //射撃
					 if(shyuukai==0){

						 motor1(1000,1000);
						 motor2(1000,1000);
						 motor3(1000,1000);
						 HAL_Delay(300);

				  		  servo(90,30,30,90);
				  		  HAL_Delay(100);
				  		servo(90,100,95,90);
						  xprintf(" Rx[0]=%d", Rxbuf[0]);
						  xprintf(" Rx[1]=%d", Rxbuf[1]);
						  xprintf(" Rx[2]=%d", Rxbuf[2]);
						  xprintf(" data[0]=%d", data[0]);
						  xprintf(" data[1]=%d", data[1]);
						  	  xprintf("\r\n");
						  	Txbuf[0]=0xFA;
						  HAL_UART_Transmit(&huart2,(uint8_t *)Txbuf,1,0xFF);
						  HAL_UART_Transmit(&huart2,(uint8_t *)Txbuf,1,0xFF);
						  HAL_UART_Transmit(&huart2,(uint8_t *)Txbuf,1,0xFF);
						  HAL_UART_Transmit(&huart2,(uint8_t *)Txbuf,1,0xFF);
						  HAL_UART_Transmit(&huart2,(uint8_t *)Txbuf,1,0xFF);
						  HAL_UART_Transmit(&huart2,(uint8_t *)Txbuf,1,0xFF);
						  HAL_UART_Transmit(&huart2,(uint8_t *)Txbuf,1,0xFF);
						  HAL_UART_Transmit(&huart2,(uint8_t *)Txbuf,1,0xFF);
						  HAL_UART_Transmit(&huart2,(uint8_t *)Txbuf,1,0xFF);
						  HAL_UART_Transmit(&huart2,(uint8_t *)Txbuf,1,0xFF);
						  int cunttime_syageki=0;
						  int datatemp;
						  while(((data[1]&0b00100000)>>5)==0 && cunttime_syageki<1800){
							  	Txbuf[0]=0xFA;
							  HAL_UART_Transmit(&huart2,(uint8_t *)Txbuf,1,0xFF);
								if(Rxbuf[0] == 251){
									data[0]=Rxbuf[1];
									data[1]=Rxbuf[2];
								}
								else if(Rxbuf[1] == 251){
									data[0]=Rxbuf[2];
									data[1]=Rxbuf[0];
								}
								else if(Rxbuf[2] == 251){
									data[0]=Rxbuf[0];
									data[1]=Rxbuf[1];
								}
							  ics_set_pos1(1,map_a(data[0],0,180,4833,10166));

							  datatemp=data[1];
							  cunttime_syageki++;
							  if((datatemp&0b00010000)>>4==1){
								  cunttime_syageki=10000;
							  }
							  if((datatemp&0b10000000)>>7==1){
								  if((datatemp&0b01000000)>>6==1){
									  motor_move(125,90,250);
								  }
								  else{
									  motor_move(125,270,200);
								  }
							  }
							  xprintf(" Rx[0]=%d", Rxbuf[0]);
							  xprintf(" Rx[1]=%d", Rxbuf[1]);
							  xprintf(" Rx[2]=%d", Rxbuf[2]);
							  xprintf(" data[0]=%d", data[0]);
							  xprintf(" data[1]=%d", data[1]);
							  xprintf(" time=%d", cunttime_syageki);
							  xprintf("\r\n");
						  }
						 HAL_GPIO_WritePin(GPIOD,GPIO_PIN_8,1);
						 HAL_Delay(100);
						 HAL_GPIO_WritePin(GPIOD,GPIO_PIN_9,1);
						 HAL_Delay(50);
						 if(cunttime_syageki>=1800){
							 if(cunttime_syageki==10000){
								 DFPlayer_playmp3(2);
							 }
							 else{DFPlayer_playmp3(5);}
						 }else{
						 DFPlayer_playmp3(2);
						 }
						 Rxbuf[0]=0;
						 Rxbuf[1]=0;
						 Rxbuf[2]=0;
						 data[0]=90;
						 data[1]=0;

						 HAL_GPIO_WritePin(GPIOD,GPIO_PIN_8,0);
						 HAL_GPIO_WritePin(GPIOD,GPIO_PIN_9,0);
						 HAL_Delay(300);

					 }
					 ics_set_pos1(1,map_a(90,0,180,4833,10166));

					 while(TIM4->CNT>29050){//端まで移動
						 HOUI_Correction(0);
						 motor_move(125,270,500);
						 }
					 	 mofu=1;
						snens_data= line_get_data_poorly_made();
						while (mofu) {
							snens_data= line_get_data_poorly_made();
							if (snens_data>400) {mofu = 1; }
							else {
								if (snens_data <= 290 && snens_data >= 270) { mofu = 1; }
								else {mofu = 0; break;}
								if (snens_data < 180) { mofu = 0; break; }
							}
							HOUI_Correction(0);
							 motor_move(125,270,500);
						}
					 servo(90,100,95,90);
				 motor1(1000,1000);
				 motor2(1000,1000);
				 motor3(1000,1000);
				 HOUI_Correction(180);//回転
				 while(marker_count_data==3){//マーカーまで移動
					 digree_now=line_get_data_poorly_made();
					 if(line_get_marker()==10){
						 marker_count_data++;
					 }
					 if(marker_count_data_ != marker_count_data){
						 marker_count_data_=marker_count_data;
						 TIM3->CNT=30000;
					 }
					 if(digree_now<180){
						 if(digree_now==90){calc=90;}
						 calc=digree_now*(sqrt(digree_now*2.3))/16;
						 HOUI_Correction(180);
						 motor_move(125,(uint16_t)calc,700);
					 }
					 else{
						 if(digree_now==270){calc=270;}
						 calc=(360-digree_now)*(sqrt((360-digree_now)*2.3))/16;
						 HOUI_Correction(180);
						 motor_move(125,(uint16_t)(360.0-calc),700);
					 }

				 }
				 TIM3->CNT=30000;
				 while((TIM3->CNT)>29800){//少し前出る
					 digree_now=line_get_data_poorly_made();
					 if(digree_now<180){
						 calc=digree_now*(sqrt(digree_now*2.3))/16;
						 HOUI_Correction(180);
						 motor_move(125,(uint16_t)calc,800);
					 }
					 else{
						 calc=(360-digree_now)*(sqrt((360-digree_now)*2.3))/16;
						 HOUI_Correction(180);
						 motor_move(125,(uint16_t)(360.0-calc),800);
					 }
				 }

		  }

		  if(marker_count_data==5){//右水平標的
			  if((TIM3->CNT)>29600 && (TIM3->CNT)<30000){
	  			   ics_set_pos1(0,map_a((109-3),0,180,4833,10166));
		  			  DFPlayer_playmp3(5);
			  }
			  else{
				  ics_set_pos1(0,map_a(90-3,0,180,4833,10166));
			  }
		  }
		  if(marker_count_data==6){//左水平標的
			  if((TIM3->CNT)>29600 && (TIM3->CNT)<30000){
	  			   ics_set_pos1(0,map_a(66-3,0,180,4833,10166));
			  }
			  else{
				  ics_set_pos1(0,map_a(90-3,0,180,4833,10166));
			  }
		  }
		  if(marker_count_data==7){//右水平標的
			  if((TIM3->CNT)>29600 && (TIM3->CNT)<30000){
	  			   ics_set_pos1(0,map_a(110-3,0,180,4833,10166));
		  			  DFPlayer_playmp3(4);
			  }
			  else{
				  ics_set_pos1(0,map_a(90-3,0,180,4833,10166));
			  }
		  }

		  if(marker_count_data==8){//左水平標的
			  if((TIM3->CNT)>29600 && (TIM3->CNT)<30000){
	  			   ics_set_pos1(0,map_a(70-3,0,180,4833,10166));
			  }
			  else{
				  ics_set_pos1(0,map_a(90-3,0,180,4833,10166));
			  }
		  }

		  if(marker_count_data==9){//横移動

			  while((TIM3->CNT)>29900){//少し前に出る
				  digree_now=line_get_data_poorly_made();
				  if(digree_now<180){
					 calc=digree_now*(sqrt(digree_now*2.3))/16;
					 HOUI_Correction(180);
					 motor_move(125,(uint16_t)calc,800);
				 }
				 else{
					 calc=(360-digree_now)*(sqrt((360-digree_now)*2.3))/16;
					 HOUI_Correction(180);
					 motor_move(125,(uint16_t)(360.0-calc),800);
				 }
			  }
		  	  	 motor_move(0,0,0);
				 TIM4->CNT=30000;
				 while(TIM4->CNT>29530){//真ん中まで移動
					 HOUI_Correction(180);
					 motor_move(125,270,500);
					 }
				 //射撃
				 if(shyuukai==0){

					 motor1(1000,1000);
					 motor2(1000,1000);
					 motor3(1000,1000);
					 HAL_Delay(300);

			  		  servo(90,30,30,90);
			  		  HAL_Delay(100);
			  		servo(90,100,95,90);
					  xprintf(" Rx[0]=%d", Rxbuf[0]);
					  xprintf(" Rx[1]=%d", Rxbuf[1]);
					  xprintf(" Rx[2]=%d", Rxbuf[2]);
					  xprintf(" data[0]=%d", data[0]);
					  xprintf(" data[1]=%d", data[1]);
					  	  xprintf("\r\n");
					  	Txbuf[0]=0xFA;
					  HAL_UART_Transmit(&huart2,(uint8_t *)Txbuf,1,0xFF);
					  HAL_UART_Transmit(&huart2,(uint8_t *)Txbuf,1,0xFF);
					  HAL_UART_Transmit(&huart2,(uint8_t *)Txbuf,1,0xFF);
					  HAL_UART_Transmit(&huart2,(uint8_t *)Txbuf,1,0xFF);
					  HAL_UART_Transmit(&huart2,(uint8_t *)Txbuf,1,0xFF);
					  HAL_UART_Transmit(&huart2,(uint8_t *)Txbuf,1,0xFF);
					  HAL_UART_Transmit(&huart2,(uint8_t *)Txbuf,1,0xFF);
					  HAL_UART_Transmit(&huart2,(uint8_t *)Txbuf,1,0xFF);
					  HAL_UART_Transmit(&huart2,(uint8_t *)Txbuf,1,0xFF);
					  HAL_UART_Transmit(&huart2,(uint8_t *)Txbuf,1,0xFF);
					  int cunttime_syageki=0;
					  int datatemp;
					  while(((data[1]&0b00100000)>>5)==0 && cunttime_syageki<1800){
						  	Txbuf[0]=0xFA;
						  HAL_UART_Transmit(&huart2,(uint8_t *)Txbuf,1,0xFF);
							if(Rxbuf[0] == 251){
								data[0]=Rxbuf[1];
								data[1]=Rxbuf[2];
							}
							else if(Rxbuf[1] == 251){
								data[0]=Rxbuf[2];
								data[1]=Rxbuf[0];
							}
							else if(Rxbuf[2] == 251){
								data[0]=Rxbuf[0];
								data[1]=Rxbuf[1];
							}
						  ics_set_pos1(1,map_a(data[0],0,180,4833,10166));

						  datatemp=data[1];
						  cunttime_syageki++;
						  if((datatemp&0b00010000)>>4==1){
							  cunttime_syageki=10000;
						  }
						  if((datatemp&0b10000000)>>7==1){
							  if((datatemp&0b01000000)>>6==1){
								  motor_move(125,90,250);
							  }
							  else{
								  motor_move(125,270,200);
							  }
						  }
						  xprintf(" Rx[0]=%d", Rxbuf[0]);
						  xprintf(" Rx[1]=%d", Rxbuf[1]);
						  xprintf(" Rx[2]=%d", Rxbuf[2]);
						  xprintf(" data[0]=%d", data[0]);
						  xprintf(" data[1]=%d", data[1]);
						  xprintf(" time=%d", cunttime_syageki);
						  xprintf("\r\n");
					  }
					 HAL_GPIO_WritePin(GPIOD,GPIO_PIN_8,1);
					 HAL_Delay(100);
					 HAL_GPIO_WritePin(GPIOD,GPIO_PIN_9,1);
					 HAL_Delay(50);
					 if(cunttime_syageki>=1800){
						 if(cunttime_syageki==10000){
							 DFPlayer_playmp3(2);
						 }
						 else{DFPlayer_playmp3(5);}
					 }else{
					 DFPlayer_playmp3(2);
					 }
					 Rxbuf[0]=0;
					 Rxbuf[1]=0;
					 Rxbuf[2]=0;
					 data[0]=90;
					 data[1]=0;

					 HAL_GPIO_WritePin(GPIOD,GPIO_PIN_8,0);
					 HAL_GPIO_WritePin(GPIOD,GPIO_PIN_9,0);
					 HAL_Delay(300);

				 }
				 ics_set_pos1(1,map_a(90,0,180,4833,10166));

			 	 mofu=1;
				 while(TIM4->CNT>29050){//端まで移動
						 HOUI_Correction(180);
						 motor_move(125,270,500);
						 }
					snens_data= line_get_data_poorly_made();
					while (mofu) {
						snens_data= line_get_data_poorly_made();
						if (snens_data>400) {mofu = 1; }
						else {
							if (snens_data <= 285 && snens_data >= 270) { mofu = 1; }
							else {mofu = 0; break;}
							if (snens_data < 180) { mofu = 0; break; }
						}
						 HOUI_Correction(180);
						 motor_move(125,270,500);
					 }
					 motor1(1000,1000);
					 motor2(1000,1000);
					 motor3(1000,1000);
					 HAL_Delay(100);
				 HOUI_Correction(0);
				 servo(90,100,95,90);
				 while(marker_count_data==9){//マーカーまで移動
					 digree_now=line_get_data_poorly_made();
					 		if(line_get_marker()==10){
					 			marker_count_data++;
					 		}
					 		if(marker_count_data_ != marker_count_data){
					 			marker_count_data_=marker_count_data;
					  			 TIM3->CNT=30000;
					 		}
					 		if(digree_now<180){
					 			calc=digree_now*(sqrt(digree_now*2.3))/16;
					 			if(digree_now==90){calc=90;}
					 			HOUI_Correction(0);
					 			motor_move(125,(uint16_t)calc,700);
					 		}
					 		else{
					 			calc=(360-digree_now)*(sqrt((360-digree_now)*2.3))/16;
					 			if(digree_now==270){calc=270;}
					 			HOUI_Correction(0);
					 			motor_move(125,(uint16_t)(360.0-calc),700);
					 		}

				 }				 TIM3->CNT=30000;
				 while((TIM3->CNT)>29800){//少し前出る
					 digree_now=line_get_data_poorly_made();
					 if(digree_now<180){
						 calc=digree_now*(sqrt(digree_now*2.3))/16;
						 HOUI_Correction(0);
						 motor_move(125,(uint16_t)calc,800);
					 }
					 else{
						 calc=(360-digree_now)*(sqrt((360-digree_now)*2.3))/16;
						 HOUI_Correction(0);
						 motor_move(125,(uint16_t)(360.0-calc),800);
					 }
				 }
		  }

			  if(marker_count_data<3 ||marker_count_data==10){//0°方向直進移動
			  	  if(digree_now<180){
				  calc=digree_now*(sqrt(digree_now*2.3))/16;
				  if(digree_now==90){calc=90;}
				  HOUI_Correction(0);
				  motor_move(125,(uint16_t)calc,800);
			  	  }
			  	  else{
					  calc=(360-digree_now)*(sqrt((360-digree_now)*2))/16;
					  if(digree_now==270){calc=270;}
					  HOUI_Correction(0);
					  motor_move(125,(uint16_t)(360.0-calc),800);
			  	  }
			  }
			  else{
				  if(digree_now<180){//180°方向直進移動

				  calc=round(digree_now*(log(digree_now*2.3))/16);
				  if(digree_now==90){calc=90;}
				  HOUI_Correction(180);
				  motor_move(125,(uint16_t)calc,800);
			  	  }
			  	  else{
					  calc=round((360-digree_now)*(log((360-digree_now)*2.3))/16);
					  if(digree_now==270){calc=270;}
					  HOUI_Correction(180);
					  motor_move(125,(uint16_t)(360.0-calc),800);
			  	  }
			  }

				  xprintf(" m1=%d", TIM3->CNT);
				  xprintf(" m2=%d", TIM4->CNT);
				  xprintf(" m3=%d", TIM8->CNT);
				  xprintf(" count=%d",marker_count_data);
				  xprintf(" digree=%d\r\n",digree_now);

	  }
	  else{motor_move(0,0,0);}
	  HAL_GPIO_TogglePin(GPIOD,GPIO_PIN_10);

}
void test2(){/*
	  xprintf(" m1=%d", TIM3->CNT);
	  xprintf(" m2=%d", TIM4->CNT);
	  xprintf(" m3=%d", TIM8->CNT);
	ics_set_pos1(0,map_a(120,0,180,4833,10166));*/

	float calc=0;
	uint16_t digree_now;
	digree_now=line_get_data_poorly_made();
	servo(90,100,95,90);
	  while((TIM3->CNT)>29900){//少し前出る
		  digree_now=line_get_data_poorly_made();
		  if(digree_now<180){
			 calc=digree_now*(sqrt(digree_now*2))/16;
			 HOUI_Correction(0);
			 motor_move(125,(uint16_t)calc,800);
		 }
		 else{
			 calc=(360-digree_now)*(sqrt((360-digree_now)*2))/16;
			 HOUI_Correction(0);
			 motor_move(125,(uint16_t)(360.0-calc),800);
		 }
	  }
	  	  	 motor_move(0,0,0);
			 TIM4->CNT=30000;
			 while(TIM4->CNT>29530){//真ん中まで移動
				 HOUI_Correction(0);
				 motor_move(125,270,500);
				 }
			 //射撃

			 motor1(1000,1000);
			 motor2(1000,1000);
			 motor3(1000,1000);
			 HAL_Delay(300);

			  xprintf(" Rx[0]=%d", Rxbuf[0]);
			  xprintf(" Rx[1]=%d", Rxbuf[1]);
			  xprintf(" Rx[2]=%d", Rxbuf[2]);
			  xprintf(" data[0]=%d", data[0]);
			  xprintf(" data[1]=%d", data[1]);
			  	  xprintf("\r\n");
			  	Txbuf[0]=0xFA;
			  HAL_UART_Transmit(&huart2,(uint8_t *)Txbuf,1,0xFF);
			  HAL_UART_Transmit(&huart2,(uint8_t *)Txbuf,1,0xFF);
			  HAL_UART_Transmit(&huart2,(uint8_t *)Txbuf,1,0xFF);
			  HAL_UART_Transmit(&huart2,(uint8_t *)Txbuf,1,0xFF);
			  HAL_UART_Transmit(&huart2,(uint8_t *)Txbuf,1,0xFF);
			  HAL_UART_Transmit(&huart2,(uint8_t *)Txbuf,1,0xFF);
			  HAL_UART_Transmit(&huart2,(uint8_t *)Txbuf,1,0xFF);
			  HAL_UART_Transmit(&huart2,(uint8_t *)Txbuf,1,0xFF);
			  HAL_UART_Transmit(&huart2,(uint8_t *)Txbuf,1,0xFF);
			  HAL_UART_Transmit(&huart2,(uint8_t *)Txbuf,1,0xFF);
			  int cunttime_syageki=0;
			  int datatemp;
			  while(((data[1]&0b00100000)>>5)==0 && cunttime_syageki<1800){
				  	Txbuf[0]=0xFA;
				  HAL_UART_Transmit(&huart2,(uint8_t *)Txbuf,1,0xFF);
					if(Rxbuf[0] == 251){
						data[0]=Rxbuf[1];
						data[1]=Rxbuf[2];
					}
					else if(Rxbuf[1] == 251){
						data[0]=Rxbuf[2];
						data[1]=Rxbuf[0];
					}
					else if(Rxbuf[2] == 251){
						data[0]=Rxbuf[0];
						data[1]=Rxbuf[1];
					}
				  ics_set_pos1(1,map_a(data[0],0,180,4833,10166));

				  datatemp=data[1];
				  cunttime_syageki++;
				  if((datatemp&0b00010000)>>4==1){
					  cunttime_syageki=10000;
				  }
				  if((datatemp&0b10000000)>>7==1){
					  if((datatemp&0b01000000)>>6==1){
						  motor_move(125,90,250);
					  }
					  else{
						  motor_move(125,270,200);
					  }
				  }
				  xprintf(" Rx[0]=%d", Rxbuf[0]);
				  xprintf(" Rx[1]=%d", Rxbuf[1]);
				  xprintf(" Rx[2]=%d", Rxbuf[2]);
				  xprintf(" data[0]=%d", data[0]);
				  xprintf(" data[1]=%d", data[1]);
				  xprintf(" time=%d", cunttime_syageki);
				  xprintf("\r\n");
			  }
			 HAL_GPIO_WritePin(GPIOD,GPIO_PIN_8,1);
			 HAL_Delay(100);
			 HAL_GPIO_WritePin(GPIOD,GPIO_PIN_9,1);
			 HAL_Delay(50);
			 if(cunttime_syageki>=1800){
				 if(cunttime_syageki==10000){
					 DFPlayer_playmp3(2);
				 }
				 else{DFPlayer_playmp3(5);}
			 }else{
			 DFPlayer_playmp3(2);
			 }
			 Rxbuf[0]=0;
			 Rxbuf[1]=0;
			 Rxbuf[2]=0;
			 data[0]=90;
			 data[1]=0;

			 HAL_GPIO_WritePin(GPIOD,GPIO_PIN_8,0);
			 HAL_GPIO_WritePin(GPIOD,GPIO_PIN_9,0);
			 HAL_Delay(300);

			 ics_set_pos1(1,map_a(90,0,180,4833,10166));

	  		  servo(90,30,30,90);
			 while(TIM4->CNT>29200){//端まで移動
				 HOUI_Correction(0);
				 motor_move(125,270,500);
				 }
			 //対岸まで移動

				int snens_data;
				int mofu=1;
				snens_data= line_get_data_poorly_made();
				while (mofu) {
					snens_data= line_get_data_poorly_made();
					if (snens_data>400) {mofu = 1; }
					else {
						if (snens_data <= 300 && snens_data >= 270) { mofu = 1; }
						else {mofu = 0; break;}
						if (snens_data < 180) { mofu = 0; break; }
					}
					HOUI_Correction(0);
					 motor_move(125,270,500);
				}

		 servo(90,100,95,90);
		 motor1(1000,1000);
		 motor2(1000,1000);
		 motor3(1000,1000);
		 HOUI_Correction(180);//回転
		 while(marker_count_data==1){//マーカーまで移動
			 digree_now=line_get_data_poorly_made();
			 if(line_get_marker()==10){
				 marker_count_data++;
			 }
			 if(marker_count_data_ != marker_count_data){
				 marker_count_data_=marker_count_data;
				 TIM3->CNT=30000;
			 }
			 if(digree_now<180){
				 if(digree_now==90){calc=90;}
				 calc=digree_now*(sqrt(digree_now*2))/16;
				 HOUI_Correction(180);
				 motor_move(125,(uint16_t)calc,800);
			 }
			 else{
				 if(digree_now==270){calc=270;}
				 calc=(360-digree_now)*(sqrt((360-digree_now)*2))/16;
				 HOUI_Correction(180);
				 motor_move(125,(uint16_t)(360.0-calc),800);
			 }

		 }
		 	 HAL_Delay(100000000);
	  HAL_GPIO_TogglePin(GPIOD,GPIO_PIN_10);
}

void test(){

	ics_set_pos1(1,map_a(130,0,180,4833,10166));
	ics_set_pos1(0,map_a(128-3,0,180,4833,10166));
	  HAL_GPIO_TogglePin(GPIOD,GPIO_PIN_10);
	  Txbuf[0]=0xFA;
	  HAL_UART_Transmit(&huart2,(uint8_t *)Txbuf,1,0xFF);
	  xprintf(" Rx[0]=%d", Rxbuf[0]);
	  xprintf(" Rx[1]=%d", Rxbuf[1]);
	  xprintf(" Rx[2]=%d", Rxbuf[2]);
	  xprintf(" data[0]=%d", data[0]);
	  xprintf(" data[1]=%d", data[1]);
	  	  xprintf("\r\n");
}

void state_print(){
	  xprintf(" SW1=%d",HAL_GPIO_ReadPin(GPIOC,GPIO_PIN_14));
	  xprintf(" SW2=%d",HAL_GPIO_ReadPin(GPIOC,GPIO_PIN_13));
	  xprintf(" SW3=%d",HAL_GPIO_ReadPin(GPIOE,GPIO_PIN_6));
	  xprintf(" SW_C=%d",HAL_GPIO_ReadPin(GPIOC,GPIO_PIN_15));
	  xprintf(" SW_S=%d",ADCdata1[1]);
	  xprintf(" m1=%d", TIM3->CNT);
	  xprintf(" m2=%d", TIM4->CNT);
	  xprintf(" m3=%d", TIM8->CNT);
	  xprintf(" 1=%d",Linedata[0]);
	  xprintf(" 2=%d",Linedata[1]);
	  xprintf(" 3=%d",Linedata[2]);
	  xprintf(" 4=%d",Linedata[3]);
	  xprintf(" 5=%d",Linedata[4]);
	  xprintf(" 6=%d",Linedata[5]);
	  xprintf(" 7=%d",Linedata[6]);
	  xprintf(" 8=%d",Linedata[7]);
	  xprintf(" 9=%d",Linedata[8]);
	  xprintf(" 10=%d",Linedata[9]);
	  xprintf(" 11=%d",Linedata[10]);
	  xprintf(" 12=%d",Linedata[11]);
	  xprintf(" 13=%d",Linedata[12]);
	  xprintf(" 14=%d",Linedata[13]);
	  xprintf(" 15=%d",Linedata[14]);
	  xprintf(" 16=%d",Linedata[15]);
	  xprintf(" 17=%d",Linedata[16]);
	  xprintf(" 18=%d",Linedata[17]);
	  xprintf(" 19=%d",Linedata[18]);
	  xprintf(" 20=%d",Linedata[19]);
	  xprintf(" 21=%d",Linedata[20]);
	  xprintf(" 22=%d",Linedata[21]);
	  xprintf(" 23=%d",Linedata[22]);
	  xprintf(" 24=%d",Linedata[23]);
	  xprintf(" R1=%d",Linedata_R[0]);
	  xprintf(" R2=%d",Linedata_R[1]);
	  xprintf(" R3=%d",Linedata_R[0]);
	  xprintf(" L1=%d",Linedata_L[0]);
	  xprintf(" L2=%d",Linedata_L[1]);
	  xprintf(" L3=%d",Linedata_L[2]);
	  xprintf(" Dig=%d",JY901_yaw_get(HOUI_def));
	  xprintf(" theta=%d",line_get_data_poorly_made());
	  xprintf(" marker=%d", line_get_marker());
	  xprintf("\r\n");
	  HAL_Delay(50);
	  HAL_GPIO_TogglePin(GPIOD,GPIO_PIN_10);
}

void Calibration(){
	while(HAL_GPIO_ReadPin(GPIOC,GPIO_PIN_15)==1){
	motor_move(0,0,0);
	oled_returnhome();
	oled_puts("Calib select    ");
	oled_setcursor(1,0);
	oled_puts("turn on startSW ");
	HAL_Delay(5);
    if(HAL_GPIO_ReadPin(GPIOF,GPIO_PIN_9)==0){	//press RS
    DFPlayer_playmp3(8);
	oled_clear();
	oled_returnhome();
	oled_puts("Angular velocity");
	oled_setcursor(1,0);
	oled_puts("    Calibration ");
	JY901_calibration(2000,1);
	oled_clear();
	oled_returnhome();
	oled_puts("Magnetic");
	oled_setcursor(1,0);
	oled_puts(" Calibration  RS");
	xprintf("houi cab\r\n");
	motor_move(200,0,200);
	JY901_calibration(12000,2);
	motor_move(0,0,0);
	oled_clear();
	oled_returnhome();
	oled_puts("Calibration End ");
	xprintf("cab end\r\n");
	JY901_calibration(100,3);
	xprintf("save\r\n");
	JY901_calibration(100,4);
	DFPlayer_stopmp3();
}
}
}

void HAL_UART_RxCpltCallback(UART_HandleTypeDef *huart){
	if(Rxbuf[0] == 251){
		data[0]=Rxbuf[1];
		data[1]=Rxbuf[2];
	}
	else if(Rxbuf[1] == 251){
		data[0]=Rxbuf[2];
		data[1]=Rxbuf[0];
	}
	else if(Rxbuf[2] == 251){
		data[0]=Rxbuf[0];
		data[1]=Rxbuf[1];
	}
	else{
		data[0]=90;
		data[1]=0;
	}
}

/* USER CODE END 4 */

void _Error_Handler(char *file, int line)
{
  while(1)
  {
  }
}

/************************ (C) COPYRIGHT STMicroelectronics *****END OF FILE****/
